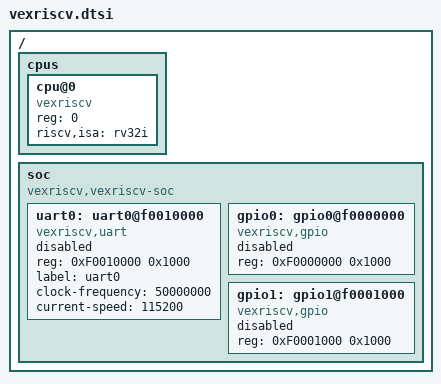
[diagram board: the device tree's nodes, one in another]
/*
 * Copyright (c) 2019 Phytec Messtechnik GmbH
 *
 * SPDX-License-Identifier: Apache-2.0
 */

#include <dt-bindings/gpio/gpio.h>

/ {
	#address-cells = <1>;
	#size-cells = <1>;

	cpus {
		#address-cells = <1>;
		#size-cells = <0>;
		cpu@0 {
			compatible = "vexriscv", "riscv";
			reg = <0>;
			device_type = "cpu";
			riscv,isa = "rv32i";
		};
	};

	soc {
		#address-cells = <1>;
		#size-cells = <1>;
		compatible = "vexriscv,vexriscv-soc", "simple-bus";
		ranges;

		uart0: uart0@f0010000 {
			compatible = "vexriscv,uart";
			reg = <0xF0010000 0x1000>;
			label = "uart0";
			clock-frequency = <50000000>;
			current-speed = <115200>;
			status = "disabled";
		};

		gpio0: gpio0@f0000000 {
			compatible = "vexriscv,gpio";
			reg = <0xF0000000 0x1000>;
			#gpio-cells = <2>;
			status = "disabled";
		};

		gpio1: gpio1@f0001000 {
			compatible = "vexriscv,gpio";
			reg = <0xF0001000 0x1000>;
			#gpio-cells = <2>;
			status = "disabled";
		};
	};
};
